# BlueNRG1 register map
Vendor: STMicroelectronics; Series: BlueNRG1; File version: 2.0.0
CPU: CM0 r0p0, little endian, no MPU, no FPU, 2 interrupt priority bits
Registers are 32-bit, read-write, reset 0x0 unless marked. A register's access mark holds for its fields unless they carry their own. Offsets are from the block's base; [hi:lo] are bit positions; {n}, {i} and the like mark numbered series; 'fields as' and 'values as' point back to an identical list; <NAME> marks a mode.

## UART
Base 0x40300000
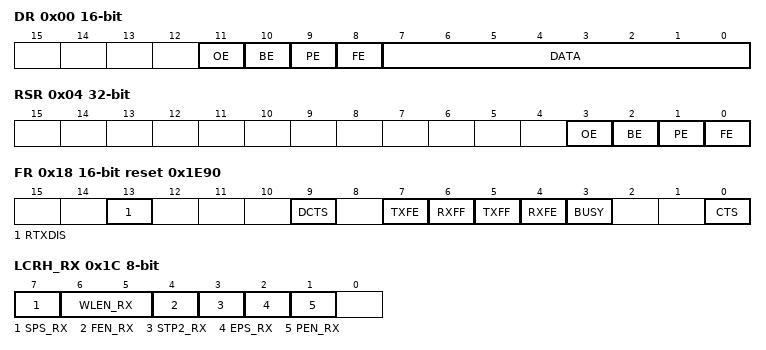
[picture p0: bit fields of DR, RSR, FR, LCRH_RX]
0x00 DR 16-bit — Data Register
  [11] OE ro — Overrun error. This bit is set to 1 if data is received and the receive FIFO is already full. This is cleared to 0b once there is an empty space in the FIFO and a new character can be written to it. The FIFO content remains valid since no further data is written when the FIFO is full, only the content of the shift register is overwritten.
  [10] BE ro — Break error. This bit is set to 1 if a break condition was detected, indicating that the received data input was held low for longer than a full-word transmission time (defined as start, data, parity and stop bits). In FIFO mode, this error is associated with the character at the top of the FIFO. When a break occurs, only one 0 character is loaded into the FIFO. The next character is only enabled after the receive data input goes to HIGH (marking state), and the next valid start bit is received
  [9] PE ro — Parity error. This bit is set to 1 if the parity of the received data character does not match the parity selected as defined by bits 2 and 7 of the LCRH_RX register. In FIFO mode, this error is associated with the character at the top of the FIFO.
  [8] FE ro — Frame error. This bit is set to 1 if the received character did not have a valid stop bit. In FIFO mode, this error is associated with the character at the top of the FIFO.
  [7:0] DATA — UART data register: <ul><li>Receive: read data character.</li><li>Transmit: write data character.</li></ul>
0x04 RSR ro — Receive Status Register
  [3] OE — Overrun error. This bit is set to 1 if data is received and the receive FIFO is already full. This is cleared to 0 by a write to ECR (data value is not important). The FIFO contents remain valid since no further data is written when the FIFO is full, only the content of the shift register are overwritten. The CPU or DMA must now read the data in order to empty the FIFO.
  [2] BE — Break error. This bit is set to 1 if a break condition was detected, indicating that the received data input was held low for longer than a full-word transmission time (defined as start, data, parity and stop bits). This bit is cleared to 0b after a write to ECR. In FIFO mode, this error is associated with the character at the top of the FIFO. When a break occurs, only one 0 character is loaded into the FIFO. The next character is only enabled after the receive data input goes to HIGH (marking state), and the next valid start bit is received.
  [1] PE — Parity error. This bit is set to 1 if the parity of the received data character does not match the parity selected as defined by bits 2 and 7 of the LCRH_RX register.This bit is cleared to 0b after a write to ECR. In FIFO mode, this error is associated with the character at the top of the FIFO.
  [0] FE — Frame error. This bit is set to 1 if the received character did not have a valid stop bit (a valid stop bit is 1).This bit is cleared to 0b after a write to ECR. In FIFO mode, this error is associated with the character at the top of the FIFO.
0x04 ECR (alternate view of RSR) — Error Clear Register. A write to this register clears the framing (FE), parity (PE), break (BE), and overrun (OE) errors.
0x0C TIMEOUT reset 0x1FF
  [21:0] PERIOD — Timeout period configuration. This bit field contains the timeout period for the UART timeout interrupt assertion. The receive timeout interrupt is asserted when the receive FIFO is not empty and no further data is received over a programmed timeout period. The duration before the timeout interrupt will assert is calculated by the following formula:<p>Timeout_Duration = (TIMEOUT_PERIOD) / (OVSP * Baud_Rate)</p>or<p>Timeout_Duration = (TIMEOUT_PERIOD) * Baud_Divisor * Tuartclk</p>
0x18 FR 16-bit ro reset 0x1E90 — Flag Register
  [13] RTXDIS — Remote Transmitter Disabled (software flow control). This bit indicates an Xoff character was sent to the remote transmitter to stop it after the received FIFO has passed over its trigger limit. This bit is cleared when a Xon character is sent to the remote transmitter.
  [9] DCTS — Delta Clear To Send. This bit is set CTS changes since the last read of the FR register.
  [7] TXFE — Transmit FIFO empty. If the FIFO is disabled (bit FEN = 0b), this bit is set when the transmit holding register is empty. If the FIFO is enabled (FEN = 1b), the TXFE bit is set when the transmit FIFO is empty.
  [6] RXFF — Receive FIFO full. If the FIFO is disabled (bit FEN = 0b), this bit is set when the receive holding register is full. If the FIFO is enabled (FEN = 1b), the RXFF bit is set when the receive FIFO is full.
  [5] TXFF — Transmit FIFO full. If the FIFO is disabled (bit FEN = 0b), this bit is set when the transmit holding register is full. If the FIFO is enabled (FEN = 1b), the TXFF bit is set when the transmit FIFO is full.
  [4] RXFE — Receive FIFO empty. If the FIFO is disabled (bit FEN = 0b), this bit is set when the receive holding register is empty. If the FIFO is enabled (FEN = 1b), the RXFE bit is set when the receive FIFO is empty.
  [3] BUSY — UART Busy. If this bit is set to 1, the UART is busy transmitting data. This bit remains set until the complete byte, including all the stop bits, has been sent from the shift register. However, if the transmit section of the UART is disabled in the middle of a transmission, the BUSY bit gets cleared. This bit is set again once the transmit section is re-enabled to complete the remaining transmission.This bit is set as soon as the transmit FIFO becomes nonempty (regardless of whether the UART is enabled or not).
  [0] CTS — Clear to send.
0x1C LCRH_RX 8-bit — Receive Line Control Register
  [7] SPS_RX — RX stick parity select:<ul><li>0: stick parity is disabled.</li><li>1: when PEN_RX = 1b (parity enabled) and EPS_RX = 1b (even parity), the parity is checked as a 0. When PEN_RX = 1b and EPS_RX = 0b (odd parity), the parity bit is checked as a 1.</li></ul>
    0=STICK_PARITY_DISABLE; 1=STICK_PARITY_ENABLE
  [6:5] WLEN_RX — RX Word length. This bit field indicates the number of data bits received in a frame as follows:<ul><li>00b: 5 bits.</li><li>01b: 6 bits.</li><li>10b: 7 bits.</li><li>11b: 8 bits.</li></ul>
    {v}=BIT{v+5} ({v+5} bits) (v=0..3)
  [4] FEN_RX — RX enable FIFOs. This bit enables/disables the receive RX FIFO buffer:<ul><li>0: RX FIFO is disabled (character mode).</li><li>1: RX FIFO is enabled.</li></ul>
    0=RXFIFO_DISABLED (RX FIFO is disabled); 1=RXFIFO_ENABLED (RX FIFO is enabled)
  [3] STP2_RX — RX two stop bits select. This bit enables the check for two stop bits being received:<ul><li>0: 1 stop bit received.</li><li>1: 2 stop bits received.</li></ul>
    0=STOP_BIT1 (1 stop bit received); 1=STOP_BITS2 (2 stop bits received)
  [2] EPS_RX — RX even parity selection, when the parity is enabled.<ul><li>0: Odd parity generation and checking is performed during reception, which check for an odd number of 1s in data and parity bits.</li><li>1: Even parity generation and checking is performed during reception, which check for an even number of 1s in data and parity bits.</li></ul>
    0=ODD (Odd parity generation and checking is performed during reception, which check for an odd number of 1s in data and parity bits); 1=EVEN (Even parity generation and checking is performed during reception, which check for an even number of 1s in data and parity bits)
  [1] PEN_RX — RX parity enable:<ul><li>0: Parity disabled.</li><li>1: Parity enabled.</li></ul>
    1=PARITY_ENABLE; 0=PARITY_DISABLE
0x24 IBRD 16-bit — Integer Baud Rate Register
  [15:0] DIVINT — Baud rate integer. The baud rate divisor is calculated as follows:<p>When OVSFACT = 0b in the CR register: Baud rate divisor = (Frequency (UARTCLK)/(16*Baud rate))</p><p>When OVSFACT = 1b in CR register: Baud rate divisor = (Frequency (UARTCLK)/(8*Baud rate))</p>where Frequency (UARTCLK) is the UART reference clock frequency. The baud rate divisor comprises the integer value (DIVINT) and the fractional value (DIVFRAC). The contents of the IBRD and FBRD registers are not updated until transmission or reception of the current character has completed.
0x28 FBRD 8-bit — Fractional Baud Rate Register
  [5:0] DIVFRAC — Baud rate fraction. Baud rate integer. The baud rate divisor is calculated as follows:<p>When OVSFACT = 0b in the CR register: Baud rate divisor = (Frequency (UARTCLK)/(16*Baud rate))</p><p>When OVSFACT = 1b in CR register: Baud rate divisor = (Frequency (UARTCLK)/(8*Baud rate))</p>where Frequency (UARTCLK) is the UART reference clock frequency. The baud rate divisor comprises the integer value (DIVINT) and the fractional value (DIVFRAC). The contents of the IBRD and FBRD registers are not updated until transmission or reception of the current character has completed.
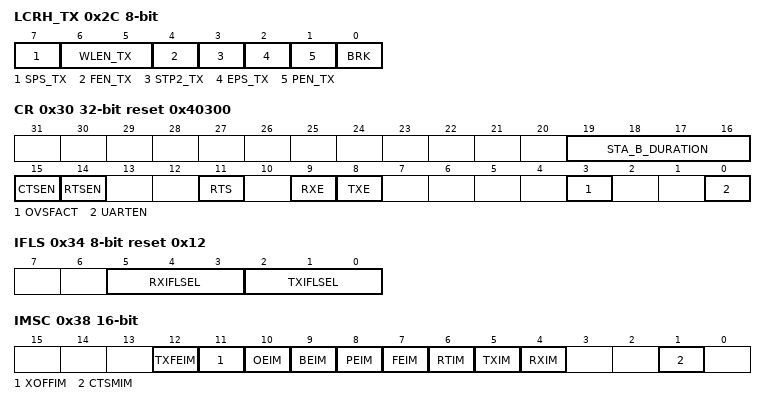
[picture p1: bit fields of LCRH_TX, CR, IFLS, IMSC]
0x2C LCRH_TX 8-bit — Transmit Line Control Register
  [7] SPS_TX — TX Stick parity check:<ul><li>0: stick parity disable.</li><li>1: when PEN_TX = 1b (parity enabled) and EPS_TX = 1b (even parity), the parity is transmitted as a 0. When PEN_TX = 1b and EPS_TX = 0b (odd parity), the parity bit is transmitted as a 1.</li></ul>
    0=STICK_PARITY_DISABLE; 1=STICK_PARITY_ENABLE
  [6:5] WLEN_TX — TX word length. This bit field indicates the number of data bits transmitted in a frame as follows:<ul><li>00b: 5 bits.</li><li>01b: 6 bits.</li><li>10b: 7 bits.</li><li>11b: 8 bits.</li></ul>
    {v}=BIT{v+5} ({v+5} bits) (v=0..3)
  [4] FEN_TX — TX Enable FIFO. This bit enables/disables the transmit TX FIFO buffer:<ul><li>0: TX FIFO is disabled (character mode), i.e. the TX FIFO becomes a 1-byte deep holding register.</li><li>1: TX FIFO is enabled.</li></ul>
    0=TXFIFO_DISABLED (TX FIFO is disabled); 1=TXFIFO_ENABLED (TX FIFO is enabled)
  [3] STP2_TX — TX two stop bits select. This bit enables the check for two stop bits being received:<ul><li>0: 1 stop bit received.</li><li>1: 2 stop bits received.</li></ul>
    values as LCRH_RX.STP2_RX
  [2] EPS_TX — TX even parity select. This bit selects the parity generation, when the parity is enabled (PEN_TX =1b). This bit has no effect when parity is disabled (PEN_TX = 0b).<ul><li>0: Odd parity generation and checking is performed during transmission, which check for an odd number of 1s in data and parity bits.</li><li>1: Even parity generation and checking is performed during transmission, which check for an even number of 1s in data and parity bits.</li></ul>
    0=ODD (Odd parity generation and checking is performed during transmission, which check for an odd number of 1s in data and parity bits); 1=EVEN (Even parity generation and checking is performed during transmission, which check for an even number of 1s in data and parity bits)
  [1] PEN_TX — TX parity enable:<ul><li>0: Parity disabled.</li><li>1: Parity Enable.</li></ul>
    1=PARITY_ENABLE; 0=PARITY_DISABLE
  [0] BRK — Send break. This bit allows a continuous low-level to be forced on TX output, after completion of the current character. This bit must be asserted for at least one complete frame transmission time in order to generate a break condition. The transmit FIFO contents remain unaffected during a break condition.<ul><li>0: Normal transmission.</li><li>1: Break condition transmission.</li></ul>
    0=TX_NORMAL (Normal transmission); 1=TX_BREAK_CONDITION (Break condition transmission)
0x30 CR reset 0x40300 (reset mask 0xFFF87) — Control Register
  [19:16] STA_B_DURATION — START bit duration Receiver state. These bits can be used to configure the START bit duration (in clock cycles) to get the bit sampled in the middle of the UART receiver. These bits can be used only when using high baud rates (IBRD = 1, FBRD >= 0 and OVSFACT = 1). Below the formula to calculate the START bit duration receiver state:<p>STA_B_DURATION = Integer(Fuartclk/(2* BAUD RATE)) - 1</p>Example: when UARTCLK = 16 MHz and BAUD RATE = 2.0 Mbps then STA_B_DURATION = 4 - 1 = 3. STA_B_DURATION field should be configured with 4'b0011.
  [15] CTSEN — CTS hardware flow control enable.<ul><li>0b: CTS disabled.</li><li>1b: CTS enabled. Data is only transmitted when the CTS is asserted.</li></ul>
    0=CTS_DISABLE (CTS hardware flow control disable); 1=CTS_ENABLE (CTS hardware flow control enable)
  [14] RTSEN — RTS hardware flow control enable.<ul><li>0b: RTS disabled.</li><li>1b: RTS enabled. Data is only requested when there is space in the receive FIFO for it to be received.</li></ul>
    0=RTS_DISABLE (RTS hardware flow control disable); 1=RTS_ENABLE (RTS hardware flow control enable)
  [11] RTS — Request to send.<ul><li>0: RTS is high.</li><li>1: RTS is low.</li></ul>
    1=REQUEST_TO_SEND_HIGH; 0=REQUEST_TO_SEND_LOW
  [9] RXE — Receive enable.<ul><li>0b: UART RX disabled.</li><li>1b: UART RX enabled.</li></ul>
    1=RX_ENABLE (Enable the RX UART); 0=RX_DISABLE (Disable the RX UART)
  [8] TXE — Transmit enable.<ul><li>0b: UART TX disabled.</li><li>1b: UART TX enabled.</li></ul>
    1=TX_ENABLE (Enable the TX UART); 0=TX_DISABLE (Disable the TX UART)
  [3] OVSFACT — UART oversampling factor.This bit enables the UART oversampling factor. If UARTCLK is 16 MHz thus max. baud-rate is 1 Mbaud when OVSFACT = 0b, and 2 Mbaud when OVSFACT = 1b.<ul><li>0: UART it is 16 UARTCLK clock cycles.</li><li>1: UART it is 8 UARTCLK clock cycles.</li></ul>
    0=Cycles_16 (16 UARTCLK clock cycles); 1=Cycles_8 (8 UARTCLK clock cycles)
  [0] UARTEN — UART enable. This bit enables the UART.<ul><li>0: UART is disabled.</li><li>1: UART is enabled. Data transmission and reception can occur. When the UART is disabled in the middle of transmission or reception, it completes the current character before stopping.</li></ul>
    1=ENABLE (Enable the UART); 0=DISABLE (Disable the UART)
0x34 IFLS 8-bit reset 0x12 — Interrupt FIFO level select register
  [5:3] RXIFLSEL — Receive interrupt FIFO level select. This bit field selects the trigger points for RX FIFO interrupt:<ul><li>000b: Interrupt when FIFO >= 1/64 full.</li><li>001b: Interrupt when FIFO >= 1/32 full.</li><li>010b: Interrupt when FIFO >= 1/16 full.</li><li>011b: Interrupt when FIFO >= 1/8 full.</li><li>100b: Interrupt when FIFO >= 1/4 full.</li><li>101b: Interrupt when FIFO >= 1/2 full.</li><li>110b: Interrupt when FIFO >= 3/4 full.</li></ul>
    0=RXFIFO_1_64 (Interrupt when FIFO >= 1/64 full); 1=RXFIFO_1_32 (Interrupt when FIFO >= 1/32 full); 2=RXFIFO_1_16 (Interrupt when FIFO >= 1/16 full); 3=RXFIFO_1_8 (Interrupt when FIFO >= 1/8 full); 4=RXFIFO_1_4 (Interrupt when FIFO >= 1/4 full); 5=RXFIFO_1_2 (Interrupt when FIFO >= 1/2 full); 6=RXFIFO_3_4 (Interrupt when FIFO >= 3/4 full)
  [2:0] TXIFLSEL — Transmit interrupt FIFO level select. This bit field selects the trigger points for TX FIFO interrupt:<ul><li>000b: Interrupt when FIFO >= 1/64 empty.</li><li>001b: Interrupt when FIFO >= 1/32 empty.</li><li>010b: Interrupt when FIFO >= 1/16 empty.</li><li>011b: Interrupt when FIFO >= 1/8 empty.</li><li>100b: Interrupt when FIFO >= 1/4 empty.</li><li>101b: Interrupt when FIFO >= 1/2 empty.</li><li>110b: Interrupt when FIFO >= 3/4 empty.</li></ul>
    0=TXFIFO_1_64 (Interrupt when FIFO >= 1/64 empty); 1=TXFIFO_1_32 (Interrupt when FIFO >= 1/32 empty); 2=TXFIFO_1_16 (Interrupt when FIFO >= 1/16 empty); 3=TXFIFO_1_8 (Interrupt when FIFO >= 1/8 empty); 4=TXFIFO_1_4 (Interrupt when FIFO >= 1/4 empty); 5=TXFIFO_1_2 (Interrupt when FIFO >= 1/2 empty); 6=TXFIFO_3_4 (Interrupt when FIFO >= 3/4 empty)
0x38 IMSC 16-bit — Interrupt Mask Set/Clear Register
  [all] fields
    1=SET_MASK (set the interrupt mask); 0=CLEAR_MASK (clear the interrupt mask)
  [12] TXFEIM — TX FIFO empty interrupt mask. On a read, the current mask for the TXFEIM interrupt is returned.<ul><li>0: Clears the mask (interrupt is disabled).</li><li>1: Sets the mask (interrupt is enabled).</li></ul>
  [11] XOFFIM — XOFF interrupt mask. On a read, the current mask for the XOFFIM interrupt is returned.<ul><li>0: Clears the mask (interrupt is disabled).</li><li>1: Sets the mask (interrupt is enabled).</li></ul>
  [10] OEIM — Overrun error interrupt mask. On a read, the current mask for the OEIM interrupt is returned.<ul><li>0: Clears the mask (interrupt is disabled).</li><li>1: Sets the mask (interrupt is enabled).</li></ul>
  [9] BEIM — Break error interrupt mask. On a read, the current mask for the BEIM interrupt is returned.<ul><li>0: Clears the mask (interrupt is disabled).</li><li>1: Sets the mask (interrupt is enabled).</li></ul>
  [8] PEIM — Parity error interrupt mask. On a read, the current mask for the PEIM interrupt is returned.<ul><li>0: Clears the mask (interrupt is disabled).</li><li>1: Sets the mask (interrupt is enabled).</li></ul>
  [7] FEIM — Framing error interrupt mask. On a read, the current mask for the FEIM interrupt is returned.<ul><li>0: Clears the mask (interrupt is disabled).</li><li>1: Sets the mask (interrupt is enabled).</li></ul>
  [6] RTIM — Receive timeout interrupt mask. On a read, the current mask for the RTIM interrupt is returned.<ul><li>0: Clears the mask (interrupt is disabled).</li><li>1: Sets the mask (interrupt is enabled).</li></ul>
  [5] TXIM — Transmit interrupt mask. On a read, the current mask for the TXIM interrupt is returned.<ul><li>0: Clears the mask (interrupt is disabled).</li><li>1: Sets the mask (interrupt is enabled).</li></ul>
  [4] RXIM — Receive interrupt mask. On a read, the current mask for the RXIM interrupt is returned.<ul><li>0: Clears the mask (interrupt is disabled).</li><li>1: Sets the mask (interrupt is enabled).</li></ul>
  [1] CTSMIM — Clear to send modem interrupt mask. On a read, the current mask for the CTSMIM interrupt is returned.<ul><li>0: Clears the mask (interrupt is disabled).</li><li>1: Sets the mask (interrupt is enabled).</li></ul>
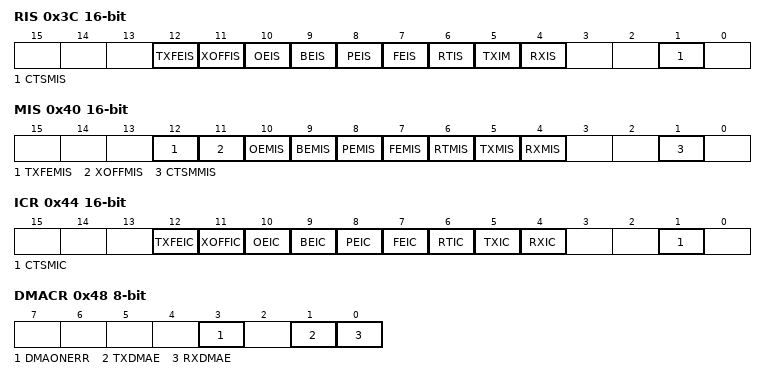
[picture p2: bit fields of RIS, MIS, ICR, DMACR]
0x3C RIS 16-bit ro — Raw Interrupt Status Register
  [all] fields
    1=INTERRUPT_PENDING; 0=INTERRUPT_NOT_PENDING
  [12] TXFEIS — TX FIFO empty interrupt status.<ul><li>0: The interrupt is not pending.</li><li>1: The interrupt is pending.</li></ul>
  [11] XOFFIS — XOFF interrupt status.<ul><li>0: The interrupt is not pending.</li><li>1: The interrupt is pending.</li></ul>
  [10] OEIS — Overrun error interrupt status.<ul><li>0: The interrupt is not pending.</li><li>1: The interrupt is pending.</li></ul>
  [9] BEIS — Break error interrupt status.<ul><li>0: The interrupt is not pending.</li><li>1: The interrupt is pending.</li></ul>
  [8] PEIS — Parity error interrupt status.<ul><li>0: The interrupt is not pending.</li><li>1: The interrupt is pending.</li></ul>
  [7] FEIS — Framing error interrupt status.<ul><li>0: The interrupt is not pending.</li><li>1: The interrupt is pending.</li></ul>
  [6] RTIS — Receive timeout interrupt status.<ul><li>0: The interrupt is not pending.</li><li>1: The interrupt is pending.</li></ul>
  [5] TXIM — Transmit interrupt status.<ul><li>0: The interrupt is not pending.</li><li>1: The interrupt is pending.</li></ul>
  [4] RXIS — Receive interrupt status.<ul><li>0: The interrupt is not pending.</li><li>1: The interrupt is pending.</li></ul>
  [1] CTSMIS — Clear to send interrupt status.<ul><li>0: The interrupt is not pending.</li><li>1: The interrupt is pending.</li></ul>
0x40 MIS 16-bit ro — Masked Interrupt Status Register
  [all] fields
    1=INTERRUPT_PENDING; 0=INTERRUPT_NOT_PENDING
  [12] TXFEMIS — TX FIFO empty masked interrupt status.<ul><li>0: The interrupt is not pending.</li><li>1: The interrupt is pending.</li></ul>
  [11] XOFFMIS — XOFF interrupt masked status.<ul><li>0: The interrupt is not pending.</li><li>1: The interrupt is pending.</li></ul>
  [10] OEMIS — Overrun error masked interrupt status.<ul><li>0: The interrupt is not pending.</li><li>1: The interrupt is pending.</li></ul>
  [9] BEMIS — Break error masked interrupt status.<ul><li>0: The interrupt is not pending.</li><li>1: The interrupt is pending.</li></ul>
  [8] PEMIS — Parity error masked interrupt status.<ul><li>0: The interrupt is not pending.</li><li>1: The interrupt is pending.</li></ul>
  [7] FEMIS — Framing error masked interrupt status.<ul><li>0: The interrupt is not pending.</li><li>1: The interrupt is pending.</li></ul>
  [6] RTMIS — Receive timeout masked interrupt status.<ul><li>0: The interrupt is not pending.</li><li>1: The interrupt is pending.</li></ul>
  [5] TXMIS — Transmit masked interrupt status.<ul><li>0: The interrupt is not pending.</li><li>1: The interrupt is pending.</li></ul>
  [4] RXMIS — Receive masked interrupt status.<ul><li>0: The interrupt is not pending.</li><li>1: The interrupt is pending.</li></ul>
  [1] CTSMMIS — Clear to send masked interrupt status.<ul><li>0: The interrupt is not pending.</li><li>1: The interrupt is pending.</li></ul>
0x44 ICR 16-bit wo write-1-clears — Interrupt Clear Register
  [12] TXFEIC — TX FIFO empty interrupt clear.<ul><li>0: No effect.</li><li>1: Clears the interrupt.</li></ul>
  [11] XOFFIC — XOFF interrupt clear.<ul><li>0: No effect.</li><li>1: Clears the interrupt.</li></ul>
  [10] OEIC — Overrun error interrupt clear.<ul><li>0: No effect.</li><li>1: Clears the interrupt.</li></ul>
  [9] BEIC — Break error interrupt clear.<ul><li>0: No effect.</li><li>1: Clears the interrupt.</li></ul>
  [8] PEIC — Parity error interrupt clear.<ul><li>0: No effect.</li><li>1: Clears the interrupt.</li></ul>
  [7] FEIC — Framing error interrupt clear.<ul><li>0: No effect.</li><li>1: Clears the interrupt.</li></ul>
  [6] RTIC — Receive timeout interrupt clear.<ul><li>0: No effect.</li><li>1: Clears the interrupt.</li></ul>
  [5] TXIC — Transmit interrupt clear.<ul><li>0: No effect.</li><li>1: Clears the interrupt.</li></ul>
  [4] RXIC — Receive interrupt clear.<ul><li>0: No effect.</li><li>1: Clears the interrupt.</li></ul>
  [1] CTSMIC — Clear to send modem interrupt clear.<ul><li>0: No effect.</li><li>1: Clears the interrupt.</li></ul>
0x48 DMACR 8-bit (reset mask 0x7) — DMA control register
  [3] DMAONERR — DMA on error.<ul><li>0: UART error interrupt status has no impact in receive DMA mode.</li><li>1: DMA receive requests are disabled when the UART error interrupt is asserted.</li></ul>
    1=DMA_ON_ERR_ENABLE (DMA receive requests are disabled when the UART error interrupt is asserted); 0=DMA_ON_ERR_DISABLE (UART error interrupt status has no impact in receive DMA mode)
  [1] TXDMAE — Transmit DMA enable bit.<ul><li>0: DMA mode is disabled for transmit.</li><li>1: DMA mode is enabled for transmit.</li></ul>
    1=DMA_MODE_TX_ENABLE (DMA mode for transmission enable); 0=DMA_MODE_TX_DISABLE (DMA mode for transmission disable)
  [0] RXDMAE — Receive DMA enable bit.<ul><li>0: DMA mode is disabled for reception.</li><li>1: DMA mode is enabled for reception.</li></ul>
    1=DMA_MODE_RX_ENABLE (DMA mode for reception enable); 0=DMA_MODE_RX_DISABLE (DMA mode for reception disable)
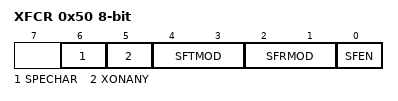
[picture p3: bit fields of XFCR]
0x50 XFCR 8-bit — XON/XOFF Control Register
  [6] SPECHAR — Special character detection bit. <ul><li>0: Special character detection disabled.</li><li>1: Special character detection enabled.</li></ul>
    1=SPECHAR_ENABLE (special character detection enabled); 0=SPECHAR_DISABLE (pecial character detection disabled)
  [5] XONANY — Xon-any bit:<ul><li>0: Incoming character must match Xon programmed value(s) to be a valid Xon.</li><li>1: Any incoming character is considered as a valid Xon.</li></ul>
    1=XONANY_ENABLE (any incoming character is considered as a valid Xon); 0=XONANY_DISABLE (incoming character must match Xon programmed value(s) to be a valid Xon)
  [4:3] SFTMOD — Software transmit flow control mode:<ul><li>00b: Transmit flow control is disabled.</li><li>01b: Xon1, Xoff1 characters are used in transmitting software flow control.</li><li>10b: Xon2, Xoff2 characters are used in transmitting software flow control.</li><li>11b: Xon1 and Xon2, Xoff1 and Xoff2 characters are used in transmitting software flow control.</li></ul>
    0=SFR_MODE_DISABLE (Transmit flow control is disable); 1=SFR_MODE_XON1_XOFF1 (Xon1, Xoff1 characters are used in transmit software flow control); 2=SFR_MODE_XON2_XOFF2 (Xon2, Xoff2 characters are used in transmit software flow control); 3=SFR_MODE_XON1_XON2_XOFF1_XOFF2 (Xon1 and Xon2, Xoff1 and Xoff2 characters are used in transmit software flow control)
  [2:1] SFRMOD — Software receive flow control mode:<ul><li>00b: Receive flow control is disabled.</li><li>01b: Xon1, Xoff1 characters are used in receiving software flow control.</li><li>10b: Xon2, Xoff2 characters are used in receiving software flow control.</li><li>11b: Xon1 and Xon2, Xoff1 and Xoff2 characters are used in receiving software flow control.</li></ul>
    0=SFR_MODE_DISABLE (Receive flow control is disable); 1=SFR_MODE_XON1_XOFF1 (Xon1, Xoff1 characters are used in receive software flow control); 2=SFR_MODE_XON2_XOFF2 (Xon2, Xoff2 characters are used in receive software flow control); 3=SFR_MODE_XON1_XON2_XOFF1_XOFF2 (Xon1 and Xon2, Xoff1 and Xoff2 characters are used in receive software flow control)
  [0] SFEN — Software flow control enable.<ul><li>0: Software flow control disable.</li><li>1: software flow control enable.</li></ul>
    1=SOFTWARE_FLOW_CTRL_ENABLE; 0=SOFTWARE_FLOW_CTRL_DISABLE
0x54 XON1 8-bit — Register used to store the Xon1 character used for software flow control
  [7:0] XON1 — Value of Xon1 character used in the software flow control
0x58 XON2 8-bit — Register used to store the Xon2 character used for software flow control
  [7:0] XON2 — Value of Xon2 character used in the software flow control
0x5C XOFF1 8-bit — Register used to store the Xoff1 character used for software flow control
  [7:0] XOFF1 — Value of Xoff1 character used in the software flow control
0x60 XOFF2 8-bit — Register used to store the Xoff2 character used for software flow control
  [7:0] XOFF2 — Value of Xoff2 character used in the software flow control

## Notices in the file
License
